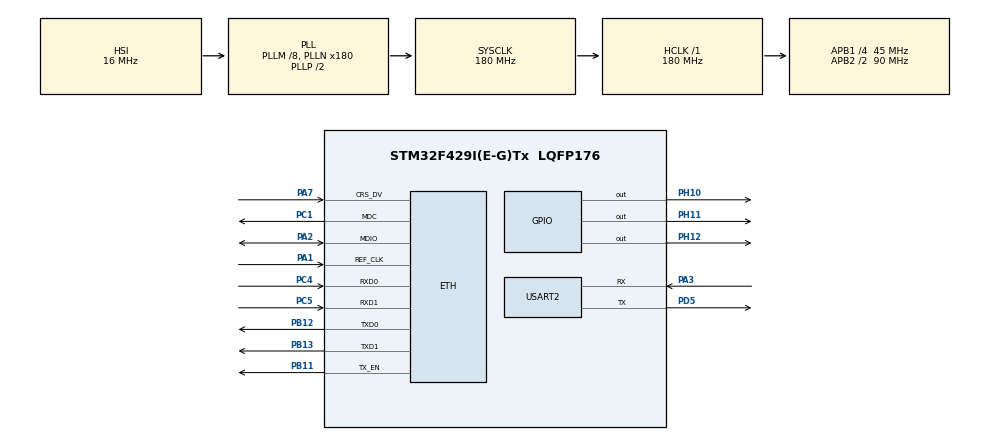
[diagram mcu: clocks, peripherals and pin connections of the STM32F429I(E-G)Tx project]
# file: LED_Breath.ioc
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ETH.MediaInterface=HAL_ETH_RMII_MODE
Mcu.Family=STM32F4
Mcu.Name=STM32F429I(E-G)Tx
Mcu.Package=LQFP176
NVIC.ETH_IRQn=true\:0\:0\:false\:true\:true\:8\:true\:true\:true
NVIC.ETH_WKUP_IRQn=true\:0\:0\:false\:true\:true\:9\:true\:true\:true
NVIC.PriorityGroup=NVIC_PRIORITYGROUP_4
NVIC.RCC_IRQn=true\:0\:0\:false\:true\:true\:1\:true\:false\:true
NVIC.TIM1_BRK_TIM9_IRQn=true\:0\:0\:false\:true\:true\:2\:true\:true\:true
NVIC.TIM1_CC_IRQn=true\:0\:0\:false\:true\:true\:5\:true\:true\:true
NVIC.TIM1_TRG_COM_TIM11_IRQn=true\:0\:0\:false\:true\:true\:4\:true\:true\:true
NVIC.TIM1_UP_TIM10_IRQn=true\:0\:0\:false\:true\:true\:3\:true\:true\:true
NVIC.TIM5_IRQn=true\:0\:0\:false\:true\:true\:7\:true\:true\:true
NVIC.USART2_IRQn=true\:0\:0\:false\:true\:true\:6\:true\:true\:true
PA1.Mode=RMII
PA1.Signal=ETH_REF_CLK
PA2.Mode=RMII
PA2.Signal=ETH_MDIO
PA3.Mode=Asynchronous
PA3.Signal=USART2_RX
PA7.Mode=RMII
PA7.Signal=ETH_CRS_DV
PB11.Mode=RMII
PB11.Signal=ETH_TX_EN
PB12.Mode=RMII
PB12.Signal=ETH_TXD0
PB13.Mode=RMII
PB13.Signal=ETH_TXD1
PC1.Mode=RMII
PC1.Signal=ETH_MDC
PC4.Mode=RMII
PC4.Signal=ETH_RXD0
PC5.Mode=RMII
PC5.Signal=ETH_RXD1
PD5.Mode=Asynchronous
PD5.Signal=USART2_TX
PH0/OSC_IN.Mode=HSE-External-Clock-Source
PH0/OSC_IN.Signal=RCC_OSC_IN
PH1/OSC_OUT.Mode=HSE-External-Clock-Source
PH1/OSC_OUT.Signal=RCC_OSC_OUT
PH10.Signal=GPIO_Output
PH11.Signal=GPIO_Output
PH12.Signal=GPIO_Output
ProjectManager.HeapSize=0x200
ProjectManager.StackSize=0x400
ProjectManager.TargetToolchain=STM32CubeIDE
RCC.48MHZClocksFreq_Value=90000000
RCC.AHBFreq_Value=180000000
RCC.APB1CLKDivider=RCC_HCLK_DIV4
RCC.APB1Freq_Value=45000000
RCC.APB1TimFreq_Value=90000000
RCC.APB2CLKDivider=RCC_HCLK_DIV2
RCC.APB2Freq_Value=90000000
RCC.APB2TimFreq_Value=180000000
RCC.CortexFreq_Value=180000000
RCC.HCLKFreq_Value=180000000
RCC.HSE_VALUE=25000000
RCC.HSI_VALUE=16000000
RCC.LSE_VALUE=32768
RCC.PLLM=8
RCC.PLLN=180
RCC.SYSCLKFreq_VALUE=180000000
RCC.SYSCLKSource=RCC_SYSCLKSOURCE_PLLCLK
RCC.VCOOutputFreq_Value=360000000
USART2.VirtualMode=VM_ASYNC
VP_TIM1_VS_ClockSourceINT.Mode=Internal
VP_TIM1_VS_ClockSourceITR.Mode=TriggerSource_ITR0
VP_TIM5_VS_ClockSourceINT.Mode=Internal
VP_TIM5_VS_ClockSourceITR.Mode=TriggerSource_ITR0
board=custom

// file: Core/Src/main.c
/* USER CODE BEGIN Header */
/**
  ******************************************************************************
  * @file           : main.c
  * @brief          : Main program body
  ******************************************************************************
  * @attention
  *
  * Copyright (c) 2025 STMicroelectronics.
  * All rights reserved.
  *
  * This software is licensed under terms that can be found in the LICENSE file
  * in the root directory of this software component.
  * If no LICENSE file comes with this software, it is provided AS-IS.
  *
  ******************************************************************************
  */
/* USER CODE END Header */
#include "main.h"
#include "string.h"

/* USER CODE BEGIN Includes */
#include "math.h"

/* USER CODE END Includes */

ETH_TxPacketConfig TxConfig;
ETH_DMADescTypeDef  DMARxDscrTab[ETH_RX_DESC_CNT]; /* Ethernet Rx DMA Descriptors */
ETH_DMADescTypeDef  DMATxDscrTab[ETH_TX_DESC_CNT]; /* Ethernet Tx DMA Descriptors */

ETH_HandleTypeDef heth;

TIM_HandleTypeDef htim1;
TIM_HandleTypeDef htim5;

UART_HandleTypeDef huart2;

void SystemClock_Config(void);
static void MX_GPIO_Init(void);
static void MX_TIM5_Init(void);
static void MX_ETH_Init(void);
static void MX_TIM1_Init(void);
static void MX_USART2_UART_Init(void);
static void MX_NVIC_Init(void);

int main(void)
{

  /* MCU Configuration--------------------------------------------------------*/

  /* Reset of all peripherals, Initializes the Flash interface and the Systick. */
  HAL_Init();

  /* Configure the system clock */
  SystemClock_Config();

  /* Initialize all configured peripherals */
  MX_GPIO_Init();
  MX_TIM5_Init();
  MX_ETH_Init();
  MX_TIM1_Init();
  MX_USART2_UART_Init();

  /* Initialize interrupts */
  MX_NVIC_Init();
  /* USER CODE BEGIN 2 */
  //HAL_TIM_PWM_Start(&htim5, TIM_CHANNEL_1); //啟用 TIMER 的 PWM 功能, CubeMX他不會自動生成這行
  //HAL_TIM_PWM_Start(&htim5, TIM_CHANNEL_2);
  //HAL_TIM_PWM_Start(&htim5, TIM_CHANNEL_3);

  //HAL_GPIO_WritePin(GPIOH, GPIO_PIN_10, GPIO_PIN_RESET);

  uint32_t pwmValue = 0;
  int direction = 1;  // 1 为亮度递增，-1 为亮度递减
  int RGB_LED = 0;
  enum LED {
      Red,    //0
      Green,  //1
      Blue    //2
  };
  /* USER CODE END 2 */

  /* Infinite loop */
  while (1)
  {

  }
}

void SystemClock_Config(void)
{
  RCC_OscInitTypeDef RCC_OscInitStruct = {0};
  RCC_ClkInitTypeDef RCC_ClkInitStruct = {0};

  /** Configure the main internal regulator output voltage
  */
  __HAL_RCC_PWR_CLK_ENABLE();
  __HAL_PWR_VOLTAGESCALING_CONFIG(PWR_REGULATOR_VOLTAGE_SCALE1);

  /** Initializes the RCC Oscillators according to the specified parameters
  * in the RCC_OscInitTypeDef structure.
  */
  RCC_OscInitStruct.OscillatorType = RCC_OSCILLATORTYPE_HSI;
  RCC_OscInitStruct.HSIState = RCC_HSI_ON;
  RCC_OscInitStruct.HSICalibrationValue = RCC_HSICALIBRATION_DEFAULT;
  RCC_OscInitStruct.PLL.PLLState = RCC_PLL_ON;
  RCC_OscInitStruct.PLL.PLLSource = RCC_PLLSOURCE_HSI;
  RCC_OscInitStruct.PLL.PLLM = 8;
  RCC_OscInitStruct.PLL.PLLN = 180;
  RCC_OscInitStruct.PLL.PLLP = RCC_PLLP_DIV2;
  RCC_OscInitStruct.PLL.PLLQ = 4;
  if (HAL_RCC_OscConfig(&RCC_OscInitStruct) != HAL_OK)
  {
    Error_Handler();
  }

  /** Activate the Over-Drive mode
  */
  if (HAL_PWREx_EnableOverDrive() != HAL_OK)
  {
    Error_Handler();
  }

  /** Initializes the CPU, AHB and APB buses clocks
  */
  RCC_ClkInitStruct.ClockType = RCC_CLOCKTYPE_HCLK|RCC_CLOCKTYPE_SYSCLK
                              |RCC_CLOCKTYPE_PCLK1|RCC_CLOCKTYPE_PCLK2;
  RCC_ClkInitStruct.SYSCLKSource = RCC_SYSCLKSOURCE_PLLCLK;
  RCC_ClkInitStruct.AHBCLKDivider = RCC_SYSCLK_DIV1;
  RCC_ClkInitStruct.APB1CLKDivider = RCC_HCLK_DIV4;
  RCC_ClkInitStruct.APB2CLKDivider = RCC_HCLK_DIV2;

  if (HAL_RCC_ClockConfig(&RCC_ClkInitStruct, FLASH_LATENCY_5) != HAL_OK)
  {
    Error_Handler();
  }
}

/**
  * @brief NVIC Configuration.
  * @retval None
  */
static void MX_NVIC_Init(void)
{
  /* RCC_IRQn interrupt configuration */
  HAL_NVIC_SetPriority(RCC_IRQn, 0, 0);
  HAL_NVIC_EnableIRQ(RCC_IRQn);
  /* TIM1_BRK_TIM9_IRQn interrupt configuration */
  HAL_NVIC_SetPriority(TIM1_BRK_TIM9_IRQn, 0, 0);
  HAL_NVIC_EnableIRQ(TIM1_BRK_TIM9_IRQn);
  /* TIM1_UP_TIM10_IRQn interrupt configuration */
  HAL_NVIC_SetPriority(TIM1_UP_TIM10_IRQn, 0, 0);
  HAL_NVIC_EnableIRQ(TIM1_UP_TIM10_IRQn);
  /* TIM1_TRG_COM_TIM11_IRQn interrupt configuration */
  HAL_NVIC_SetPriority(TIM1_TRG_COM_TIM11_IRQn, 0, 0);
  HAL_NVIC_EnableIRQ(TIM1_TRG_COM_TIM11_IRQn);
  /* TIM1_CC_IRQn interrupt configuration */
  HAL_NVIC_SetPriority(TIM1_CC_IRQn, 0, 0);
  HAL_NVIC_EnableIRQ(TIM1_CC_IRQn);
  /* USART2_IRQn interrupt configuration */
  HAL_NVIC_SetPriority(USART2_IRQn, 0, 0);
  HAL_NVIC_EnableIRQ(USART2_IRQn);
  /* TIM5_IRQn interrupt configuration */
  HAL_NVIC_SetPriority(TIM5_IRQn, 0, 0);
  HAL_NVIC_EnableIRQ(TIM5_IRQn);
  /* ETH_IRQn interrupt configuration */
  HAL_NVIC_SetPriority(ETH_IRQn, 0, 0);
  HAL_NVIC_EnableIRQ(ETH_IRQn);
  /* ETH_WKUP_IRQn interrupt configuration */
  HAL_NVIC_SetPriority(ETH_WKUP_IRQn, 0, 0);
  HAL_NVIC_EnableIRQ(ETH_WKUP_IRQn);
}

static void MX_ETH_Init(void)
{

   static uint8_t MACAddr[6];

  heth.Instance = ETH;
  MACAddr[0] = 0x00;
  MACAddr[1] = 0x80;
  MACAddr[2] = 0xE1;
  MACAddr[3] = 0x00;
  MACAddr[4] = 0x00;
  MACAddr[5] = 0x00;
  heth.Init.MACAddr = &MACAddr[0];
  heth.Init.MediaInterface = HAL_ETH_RMII_MODE;
  heth.Init.TxDesc = DMATxDscrTab;
  heth.Init.RxDesc = DMARxDscrTab;
  heth.Init.RxBuffLen = 1524;

  if (HAL_ETH_Init(&heth) != HAL_OK)
  {
    Error_Handler();
  }

  memset(&TxConfig, 0 , sizeof(ETH_TxPacketConfig));
  TxConfig.Attributes = ETH_TX_PACKETS_FEATURES_CSUM | ETH_TX_PACKETS_FEATURES_CRCPAD;
  TxConfig.ChecksumCtrl = ETH_CHECKSUM_IPHDR_PAYLOAD_INSERT_PHDR_CALC;
  TxConfig.CRCPadCtrl = ETH_CRC_PAD_INSERT;

}

static void MX_TIM1_Init(void)
{

  TIM_ClockConfigTypeDef sClockSourceConfig = {0};
  TIM_SlaveConfigTypeDef sSlaveConfig = {0};
  TIM_MasterConfigTypeDef sMasterConfig = {0};

  htim1.Instance = TIM1;
  htim1.Init.Prescaler = 0;
  htim1.Init.CounterMode = TIM_COUNTERMODE_UP;
  htim1.Init.Period = 65535;
  htim1.Init.ClockDivision = TIM_CLOCKDIVISION_DIV1;
  htim1.Init.RepetitionCounter = 0;
  htim1.Init.AutoReloadPreload = TIM_AUTORELOAD_PRELOAD_DISABLE;
  if (HAL_TIM_Base_Init(&htim1) != HAL_OK)
  {
    Error_Handler();
  }
  sClockSourceConfig.ClockSource = TIM_CLOCKSOURCE_INTERNAL;
  if (HAL_TIM_ConfigClockSource(&htim1, &sClockSourceConfig) != HAL_OK)
  {
    Error_Handler();
  }
  sSlaveConfig.SlaveMode = TIM_SLAVEMODE_DISABLE;
  sSlaveConfig.InputTrigger = TIM_TS_ITR0;
  if (HAL_TIM_SlaveConfigSynchro(&htim1, &sSlaveConfig) != HAL_OK)
  {
    Error_Handler();
  }
  sMasterConfig.MasterOutputTrigger = TIM_TRGO_RESET;
  sMasterConfig.MasterSlaveMode = TIM_MASTERSLAVEMODE_DISABLE;
  if (HAL_TIMEx_MasterConfigSynchronization(&htim1, &sMasterConfig) != HAL_OK)
  {
    Error_Handler();
  }

}

static void MX_TIM5_Init(void)
{

  TIM_ClockConfigTypeDef sClockSourceConfig = {0};
  TIM_SlaveConfigTypeDef sSlaveConfig = {0};
  TIM_MasterConfigTypeDef sMasterConfig = {0};

  htim5.Instance = TIM5;
  htim5.Init.Prescaler = 0;
  htim5.Init.CounterMode = TIM_COUNTERMODE_UP;
  htim5.Init.Period = 4294967295;
  htim5.Init.ClockDivision = TIM_CLOCKDIVISION_DIV1;
  htim5.Init.AutoReloadPreload = TIM_AUTORELOAD_PRELOAD_DISABLE;
  if (HAL_TIM_Base_Init(&htim5) != HAL_OK)
  {
    Error_Handler();
  }
  sClockSourceConfig.ClockSource = TIM_CLOCKSOURCE_INTERNAL;
  if (HAL_TIM_ConfigClockSource(&htim5, &sClockSourceConfig) != HAL_OK)
  {
    Error_Handler();
  }
  sSlaveConfig.SlaveMode = TIM_SLAVEMODE_DISABLE;
  sSlaveConfig.InputTrigger = TIM_TS_ITR0;
  if (HAL_TIM_SlaveConfigSynchro(&htim5, &sSlaveConfig) != HAL_OK)
  {
    Error_Handler();
  }
  sMasterConfig.MasterOutputTrigger = TIM_TRGO_RESET;
  sMasterConfig.MasterSlaveMode = TIM_MASTERSLAVEMODE_DISABLE;
  if (HAL_TIMEx_MasterConfigSynchronization(&htim5, &sMasterConfig) != HAL_OK)
  {
    Error_Handler();
  }

}

static void MX_USART2_UART_Init(void)
{

  huart2.Instance = USART2;
  huart2.Init.BaudRate = 115200;
  huart2.Init.WordLength = UART_WORDLENGTH_8B;
  huart2.Init.StopBits = UART_STOPBITS_1;
  huart2.Init.Parity = UART_PARITY_NONE;
  huart2.Init.Mode = UART_MODE_TX_RX;
  huart2.Init.HwFlowCtl = UART_HWCONTROL_NONE;
  huart2.Init.OverSampling = UART_OVERSAMPLING_16;
  if (HAL_UART_Init(&huart2) != HAL_OK)
  {
    Error_Handler();
  }

}

static void MX_GPIO_Init(void)
{
  GPIO_InitTypeDef GPIO_InitStruct = {0};

  /* GPIO Ports Clock Enable */
  __HAL_RCC_GPIOH_CLK_ENABLE();
  __HAL_RCC_GPIOC_CLK_ENABLE();
  __HAL_RCC_GPIOA_CLK_ENABLE();
  __HAL_RCC_GPIOB_CLK_ENABLE();
  __HAL_RCC_GPIOD_CLK_ENABLE();

  /*Configure GPIO pin Output Level */
  HAL_GPIO_WritePin(GPIOH, GPIO_PIN_10|GPIO_PIN_11|GPIO_PIN_12, GPIO_PIN_RESET);

  /*Configure GPIO pins : PH10 PH11 PH12 */
  GPIO_InitStruct.Pin = GPIO_PIN_10|GPIO_PIN_11|GPIO_PIN_12;
  GPIO_InitStruct.Mode = GPIO_MODE_OUTPUT_PP;
  GPIO_InitStruct.Pull = GPIO_NOPULL;
  GPIO_InitStruct.Speed = GPIO_SPEED_FREQ_LOW;
  HAL_GPIO_Init(GPIOH, &GPIO_InitStruct);

}

void Error_Handler(void)
{
  __disable_irq();
  while (1)
  {
  }
}
